# 3065PNPIRA register map
File version: 1.0
Registers are 32-bit, access per field, reset 0x0 unless marked. A register's access mark holds for its fields unless they carry their own. Offsets are from the block's base; [hi:lo] are bit positions; {n}, {i} and the like mark numbered series.

## FLASH — FLASH peripheral interface
Base 0x14710000
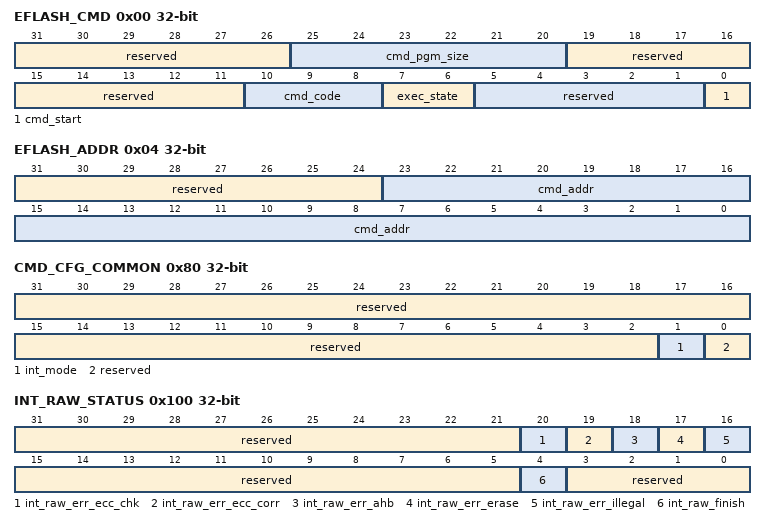
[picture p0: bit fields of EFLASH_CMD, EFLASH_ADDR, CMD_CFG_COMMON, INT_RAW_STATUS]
0x00 EFLASH_CMD — EFLASH_CMD为命令寄存器。
  [31:26] reserved ro — 保留。
  [25:20] cmd_pgm_size rw — Program Size寄存器，Unit:Word（32bit）。 0x0：2； 0x1：4； 0x2：8； … 0x0F：60； 0x10：64； 其他：非法值。 cmd_addr + cmd_pgm_size寻址范围不能跨越Flash-Row（64Word），cmd_addr需要按64bit对齐。
  [19:11] reserved ro — 保留。
  [10:8] cmd_code rw — 操作字寄存器。 010：MAIN Program； 011：INFO Program； 100：MAIN Erase； 101：INFO Erase； 110：Mass Erase（Only Main区，不含INFO区）； 其他：无操作。
  [7:6] exec_state ro — Flash CMD执行状态debug寄存器。 00（IDLE）：无操作或操作已完成； 01（RUNNING）：有操作在执行； 10（FINISH）：操作完成，但完成标示未清除（中断模式才生效）； 11：保留。
  [5:1] reserved ro — 保留。
  [0] cmd_start rw — Flash CMD操作启动寄存器。 写1启动Flash CMD操作； 写0无影响； 读1 Flash CMD操作未完成； 读0 Flash CMD操作完成或无操作。
0x04 EFLASH_ADDR — EFLASH_ADDR为地址寄存器。
  [31:24] reserved ro — 保留。
  [23:0] cmd_addr rw — Program或者Erase的起始地址寄存器，Unit:Byte（8bit）。 Main Region起始地址：0x00_0000； Information Region起始地址：0x80_0000。 注意：控制器自动忽略低2bit地址。
0x80 CMD_CFG_COMMON — CMD_CFG_COMMON为Flash CMD配置寄存器。
  [31:2] reserved ro — 保留。
  [1] int_mode rw — Flash CMD操作方式控制寄存器。 0：轮询方式； 1：中断方式，此方式Flash CMD操作完成后需要配置int_clr_finish清除完成标识，方可进行下一次操作。
  [0] reserved ro — 保留。
0x100 INT_RAW_STATUS ro — INT_RAW_STATUS为中断原始状态寄存器。
  [31:21] reserved — 保留。
  [20] int_raw_err_ecc_chk — Main Region或Information Region 读数据ECC检验错误原始中断寄存器。 0：无错误，或者读数据ECC检错功能未使能； 1：发生ECC检查错误。
  [19] int_raw_err_ecc_corr — Main Region或Information Region 读数据ECC纠正错误原始中断寄存器。 0：无错误，或者读数据ECC纠错功能未使能； 1：发生无法纠正的ECC错误。
  [18] int_raw_err_ahb — AHB请求错误原始中断寄存器。 0：无错误； 1：AHB读请求地址超过Main Region或Information Region范围或发生了AHB写请求。
  [17] int_raw_err_erase — 擦除错误原始中断状态寄存器。 0：擦除操作Verify成功； 1：擦除操作Verify失败。
  [16] int_raw_err_illegal — 非法Flash CMD操作错误原始中断寄存器。 0：无错误； 1：存在Flash CMD操作错误，具体错误，需要查询FLASH_STATUS寄存器。
  [15:5] reserved — 保留。
  [4] int_raw_finish — Flash CMD操作完成原始中断寄存器。 0：无操作或者操作未完成； 1：操作已完成。
  [3:0] reserved — 保留。
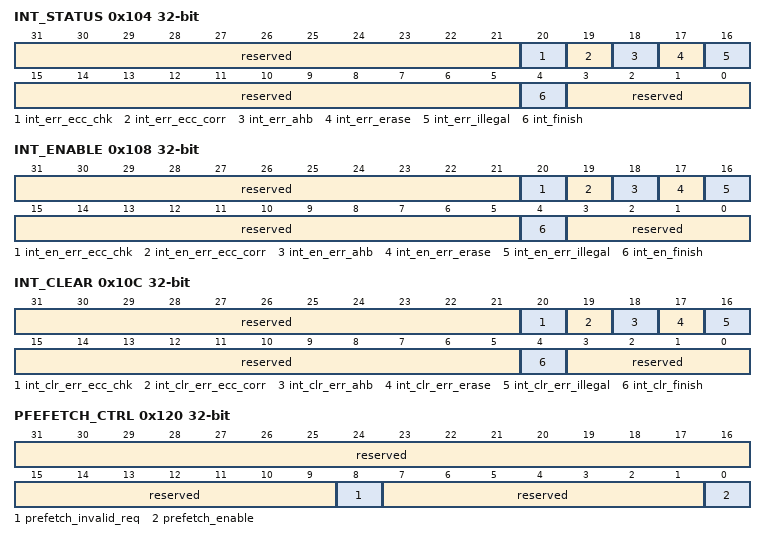
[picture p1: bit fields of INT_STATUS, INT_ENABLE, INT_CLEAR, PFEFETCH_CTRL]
0x104 INT_STATUS ro — INT_STATUS为中断状态寄存器。
  [31:21] reserved — 保留。
  [20] int_err_ecc_chk — Main Region或Information Region读数据ECC检验错误中断状态寄存器。 0：无错误，或者读数据ECC检错功能未使能； 1：发生ECC检查错误。
  [19] int_err_ecc_corr — Main Region或Information Region 读数据ECC纠正错误中断状态寄存器。 0：无错误，或者读数据ECC纠错功能未使能； 1：发生无法纠正的ECC错误。
  [18] int_err_ahb — AHB请求错误中断状态寄存器。 0：无错误； 1：AHB读请求地址超过Main Region或Information Region范围或发生了AHB写请求。
  [17] int_err_erase — 擦除错误中断状态寄存器。 0：擦除操作Verify成功； 1：擦除操作Verify失败。
  [16] int_err_illegal — 非法Flash CMD操作错误中断状态寄存器。 0：无错误； 1：存在Flash CMD操作错误，具体错误，需要查询FLASH_STATUS寄存器。
  [15:5] reserved — 保留。
  [4] int_finish — Flash CMD操作完成中断状态寄存器。 0：无操作或者操作未完成； 1：操作已完成。
  [3:0] reserved — 保留。
0x108 INT_ENABLE — INT_ENABLE为中断使能配置寄存器。
  [31:21] reserved ro — 保留。
  [20] int_en_err_ecc_chk rw — Main Region或Information Region读数据ECC检验错误中断使能寄存器。 0：不使能，上报原始中断，不上报中断状态，不上报CPU中断； 1：使能，上报原始中断，上报中断状态，上报CPU中断。
  [19] int_en_err_ecc_corr rw — Main Region或Information Region读数据ECC纠正错误中断使能寄存器。 0：不使能，上报原始中断，不上报中断状态，不上报CPU中断； 1：使能，上报原始中断，上报中断状态，上报CPU中断。
  [18] int_en_err_ahb rw — AHB请求错误中断使能寄存器。 0：不使能，上报原始中断，不上报中断状态，不上报CPU中断； 1：使能，上报原始中断，上报中断状态，上报CPU中断。
  [17] int_en_err_erase rw — 擦除错误中断使能寄存器。 0：不使能，上报原始中断，不上报中断状态，不上报CPU中断； 1：使能，上报原始中断，上报中断状态，上报CPU中断。
  [16] int_en_err_illegal rw — 非法Flash CMD操作错误中断使能寄存器。 0：不使能，上报原始中断，不上报中断状态，不上报CPU中断； 1：使能，上报原始中断，上报中断状态，上报CPU中断。
  [15:5] reserved ro — 保留。
  [4] int_en_finish rw — Flash CMD操作完成中断使能寄存器。 0：不使能，上报原始中断，不上报中断状态，不上报CPU中断； 1：使能，上报原始中断，上报中断状态，上报CPU中断。
  [3:0] reserved ro — 保留。
0x10C INT_CLEAR — INT_CLEAR为中断清除寄存器。
  [31:21] reserved ro — 保留。
  [20] int_clr_err_ecc_chk rw write-1-clears — Main Region或Information Region读数据ECC检验错误中断清除寄存器。 0：不清除； 1：清除原始中断与中断状态。
  [19] int_clr_err_ecc_corr rw write-1-clears — Main Region或Information Region读数据ECC纠正错误中断清除寄存器。 0：不清除； 1：清除原始中断与中断状态。
  [18] int_clr_err_ahb rw write-1-clears — AHB请求错误中断清除寄存器。 0：不清除； 1：清除原始中断与中断状态。
  [17] int_clr_err_erase rw write-1-clears — 擦除错误中断清除寄存器。 0：不清除； 1：清除原始中断与中断状态。
  [16] int_clr_err_illegal rw write-1-clears — 非法Flash CMD操作错误中断清除寄存器。 0：不清除； 1：清除原始中断与中断状态。
  [15:5] reserved ro — 保留。
  [4] int_clr_finish rw write-1-clears — Flash CMD操作完成中断清除寄存器。 0：不清除； 1：清除原始中断与中断状态。
  [3:0] reserved ro — 保留。
0x120 PFEFETCH_CTRL — PFEFETCH_CTRL为预取控制寄存器。
  [31:9] reserved ro — 保留。
  [8] prefetch_invalid_req rw — Cache数据无效请求控制寄存器。 写0：无效； 写1：请求prefetch_invalid，逻辑完成invalid后自动清除该bit； 读0：最近一次invalid请求已完成； 读1：最近一次invalid请求未完成。
  [7:1] reserved ro — 保留。
  [0] prefetch_enable rw — 预取使能控制寄存器。 0：预取使能关闭； 1：每次AHB传输完成尾地址向前预取16Byte数据（以8Byte对齐）。
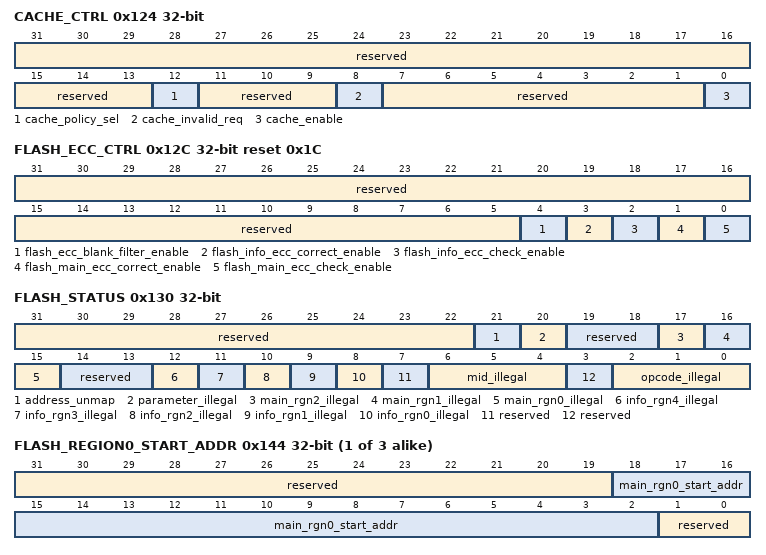
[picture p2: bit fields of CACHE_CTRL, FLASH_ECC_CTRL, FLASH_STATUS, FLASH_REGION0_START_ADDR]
0x124 CACHE_CTRL — CACHE_CTRL为Cache控制寄存器。
  [31:13] reserved ro — 保留。
  [12] cache_policy_sel rw — Cache策略选择控制寄存器。 0：Normal Cache； 1：Branch Cache。
  [11:9] reserved ro — 保留。
  [8] cache_invalid_req rw — Cache数据无效请求控制寄存器。 写0：无效； 写1：请求Cache invalid，逻辑完成invalid后自动清除该bit； 读0：最近一次invalid请求已完成； 读1：最近一次invalid请求未完成。
  [7:1] reserved ro — 保留。
  [0] cache_enable rw — Cache使能控制寄存器。 0：Cache使能关闭； 1：Cache使能打开，AHB传输数据将会查询Cache，Cache Hit则数据从Cache获取，Cache miss则数据从eFlash获取，并将此地址数据缓存进入Cache。
0x12C FLASH_ECC_CTRL reset 0x1C — FLASH_ECC_CTRL为Flash ECC检错纠错使能控制寄存器。
  [31:5] reserved ro — 保留。
  [4] flash_ecc_blank_filter_enable rw — Flash未编程区域ECC屏蔽过滤使能控制（72bit全1判断为未编程区域）。 0：不使能此功能，所有Read访问数据都根据flash_ecc_correct_enable、flash_ecc_check_enable配置进行相应的ECC检查或者纠正； 1：使能此功能，检查Read访问数据内容，只有非全1（72bit）数据根据flash_ecc_correct_enable、flash_ecc_check_enable配置进行相应的ECC检查或者纠正。
  [3] flash_info_ecc_correct_enable rw — Flash Information Region ECC纠错功能控制。 0：回读数据发生错误时，不进行ECC纠错； 1：回读数据发生1bit错误时，进行ECC纠错。
  [2] flash_info_ecc_check_enable rw — Flash Information Region 检错使能控制（Program 强制ECC打开）。 0：回读数据不进行ECC检查； 1：回读数据进行ECC检查。
  [1] flash_main_ecc_correct_enable rw — Flash Main Region ECC纠错功能控制。 0：回读数据发生错误时，不进行ECC纠错； 1：回读数据发生1bit错误时，进行ECC纠错。
  [0] flash_main_ecc_check_enable rw — Flash Main Region检错使能控制（Program强制ECC打开）。 0：回读数据不进行ECC检查； 1：回读数据进行ECC检查。
0x130 FLASH_STATUS ro — FLASH_STATUS为Flash CMD操作FLASH状态寄存器。
  [31:22] reserved — 保留。
  [21] address_unmap — Flash CMD操作地址是否越界指示寄存器。 0：无错误； 1：地址越界错误。
  [20] parameter_illegal — Flash CMD操作参数是否有效指示寄存器。 0：无错误； 1：操作参数错误。
  [19:18] reserved — 保留。
  [17] main_rgn2_illegal — Flash CMD操作main_rgn2是否发生非法访问指示寄存器。 0：无错误； 1：main_rgn2发生非法访问。
  [16] main_rgn1_illegal — Flash CMD操作main_rgn1是否发生非法访问指示寄存器。 0：无错误； 1：main_rgn1发生非法访问。
  [15] main_rgn0_illegal — Flash CMD操作main_rgn0是否发生非法访问指示寄存器。 0：无错误； 1：main_rgn0发生非法访问。
  [14:13] reserved — 保留。
  [12] info_rgn4_illegal — Flash CMD操作info_rgn4是否发生非法访问指示寄存器。 0：无错误； 1：info_rgn4发生非法访问
  [11] info_rgn3_illegal — Flash CMD操作info_rgn3是否发生非法访问指示寄存器。 0：无错误； 1：info_rgn3发生非法访问
  [10] info_rgn2_illegal — Flash CMD操作info_rgn2是否发生非法访问指示寄存器。 0：无错误； 1：info_rgn2发生非法访问。
  [9] info_rgn1_illegal — Flash CMD操作info_rgn1是否发生非法访问指示寄存器。 0：无错误； 1：info_rgn1发生非法访问。
  [8] info_rgn0_illegal — Flash CMD操作info_rgn0是否发生非法访问指示寄存器。 0：无错误； 1：info_rgn0发生非法访问。
  [7] reserved — 保留。
  [6:4] mid_illegal — 发生非法访问时，Flash CMD寄存器非法mid value。
  [3] reserved — 保留。
  [2:0] opcode_illegal — 发生非法访问时，Flash CMD寄存器非法opcode value。
0x138 AHB_ERR_ADDR ro — AHB_ERR_ADDR为AHB错误请求地址记录寄存器。
  [31:0] ahb_err_address — int_raw_err_ahb发生时，记录第一次发生AHB错误访问的地址信息，包括越界与AHB写操作。 配置中断清除寄存器int_clr_err_ahb时，该寄存器清0，并开始记录下一次错误请求地址信息。
{0x144+0xC*i} FLASH_REGION{i}_START_ADDR ro (i=0..2) — FLASH_REGION{i}_START_ADDR为MAIN REGION{i}起始地址寄存器。
  [31:19] reserved — 保留。
  [18:2] main_rgn{i}_start_addr — main_rgn{i}起始地址寄存器，Unit:Word（32bit）。
  [1:0] reserved — 保留。
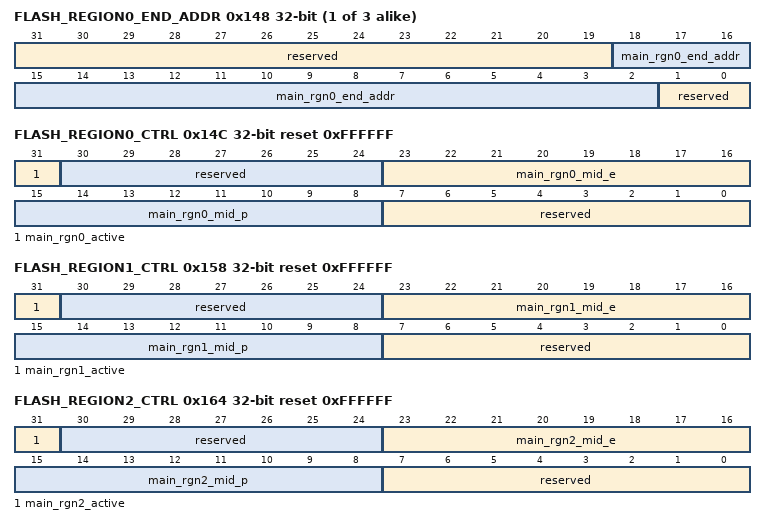
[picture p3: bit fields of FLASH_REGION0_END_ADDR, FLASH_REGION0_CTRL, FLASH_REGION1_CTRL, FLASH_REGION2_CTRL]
{0x148+0xC*i} FLASH_REGION{i}_END_ADDR ro (i=0..2) — FLASH_REGION{i}_END_ADDR为MAIN REGION{i}结束地址寄存器。
  [31:19] reserved — 保留。
  [18:2] main_rgn{i}_end_addr — main_rgn{i}结束地址寄存器，Unit:Word（32bit）。
  [1:0] reserved — 保留。
0x14C FLASH_REGION0_CTRL ro reset 0xFFFFFF — FLASH_REGION0_CTRL为MAIN REGION0控制寄存器。
  [31] main_rgn0_active — 是否激活区域访问控制寄存器。 0：不激活； 1：激活。
  [30:24] reserved — 保留。
  [23:16] main_rgn0_mid_e — 允许对main_rgn0擦除操作的mid。 bit[7:0]分别标识mid为7～0的master是否允许擦除操作。 0：禁止； 1：允许。
  [15:8] main_rgn0_mid_p — 允许对main_rgn0编程操作的mid。 bit[7:0]分别标识mid为7～0的master是否允许编程操作。 0：禁止； 1：允许。
  [7:0] reserved — 保留。
0x158 FLASH_REGION1_CTRL ro reset 0xFFFFFF — FLASH_REGION1_CTRL为MAIN REGION1控制寄存器。
  [31] main_rgn1_active — 是否激活区域访问控制寄存器。 0：不激活； 1：激活。
  [30:24] reserved — 保留。
  [23:16] main_rgn1_mid_e — 允许对main_rgn1擦除操作的mid。 bit[7:0]分别标识mid为7～0的master是否允许擦除操作。 0：禁止； 1：允许。
  [15:8] main_rgn1_mid_p — 允许对main_rgn1编程操作的mid。 bit[7:0]分别标识mid为7 ～ 0的master是否允许编程操作。[A1] 0：禁止； 1：允许。
  [7:0] reserved — 保留。
0x164 FLASH_REGION2_CTRL ro reset 0xFFFFFF — FLASH_REGION2_CTRL为MAIN REGION2控制寄存器。
  [31] main_rgn2_active — 是否激活区域访问控制寄存器。 0：不激活； 1：激活。
  [30:24] reserved — 保留。
  [23:16] main_rgn2_mid_e — 允许对main_rgn2擦除操作的mid。 bit[7:0]分别标识mid为7～0的master是否允许擦除操作。 0：禁止； 1：允许。
  [15:8] main_rgn2_mid_p — 允许对main_rgn2编程操作的mid。 bit[7:0]分别标识mid为7～0的master是否允许编程操作。 0：禁止； 1：允许。
  [7:0] reserved — 保留。
0x200 MAGIC_LOCK rw — MAGIC_LOCK为Flash CMD操作魔术字保护寄存器。
  [31:0] magic_lock — 写入0xFEDC_BA98，魔术字解锁，Flash CMD相关操作寄存器写入权限打开； 写入其他数值，魔术字锁定，Flash CMD相关操作寄存器写入权限关闭； 读出0xFEDC_BA98表示解锁，读出0表示锁定； 默认为锁定状态，Flash CMD相关操作寄存器包括：EFLASH_CMD、EFLASH_ADDR、PGM_WDATA。
0x3F0 EFLASH_CAPACITY_0 ro reset 0x80000 — EFLASH_CAPACITY_0为模块信息寄存器0。
  [31:0] main_capacity — Main Region容量指示寄存器，Unit:Byte。
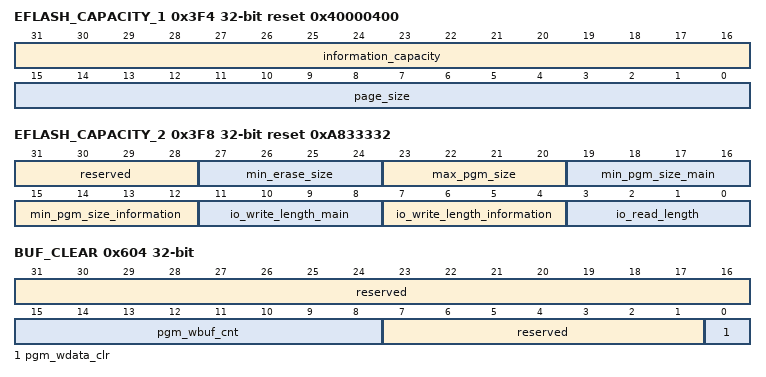
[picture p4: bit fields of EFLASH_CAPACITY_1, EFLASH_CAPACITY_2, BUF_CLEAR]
0x3F4 EFLASH_CAPACITY_1 ro reset 0x40000400 — EFLASH_CAPACITY_1为模块信息寄存器1。
  [31:16] information_capacity — Information Region容量指示寄存器，Unit:Byte。
  [15:0] page_size — eFlash Page容量指示寄存器，Unit:Byte。
0x3F8 EFLASH_CAPACITY_2 ro reset 0xA833332 — EFLASH_CAPACITY_2为模块信息寄存器2。
  [31:28] reserved — 保留。
  [27:24] min_erase_size — 最小擦除Size（2**n）。 Unit:Byte。 1KB。
  [23:20] max_pgm_size — 连续编程最大Size（2**n）。 Unit:Byte。 256Byte。
  [19:16] min_pgm_size_main — Main Region最小编程Size（2**n）。 Unit:Byte。 8Byte。
  [15:12] min_pgm_size_information — Information Region最小编程Size（2**n）。 Unit:Byte。 8Byte。
  [11:8] io_write_length_main — 写Main Region IO Size（2**n）。 Unit:Byte（不算ECC bit）。 8Byte。
  [7:4] io_write_length_information — 写Information Region IO Size（2**n）。 Unit:Byte（不算ECC bit）。 8Byte。
  [3:0] io_read_length — 读IO Size (2**n)。 Unit:Byte（不算ECC bit）。 4Byte。
0x400 PGM_WDATA wo — PGM_WDATA为编程数据寄存器。
  [31:0] pgm_wdata — 编程数据Buffer寄存器。 0x400～0x5FC，都映射到同一写数据寄存器； 写0x400~0x5FC任意一个寄存器一次，写数据Buffer数据增加一个Word（32bit），此Buffer数据先进先出。
0x604 BUF_CLEAR — BUF_CLEAR为编程数据Buffer清理寄存器。
  [31:16] reserved ro — 保留。
  [15:8] pgm_wbuf_cnt ro — 编程数据Buffer当前存量数据size指示寄存器，Unit:Word（32bit）。
  [7:1] reserved ro — 保留。
  [0] pgm_wdata_clr rw write-1-clears — 编程数据Buffer数据清除控制寄存器。 写0：无效果； 写1：清除当前Buffer中残留数据。
